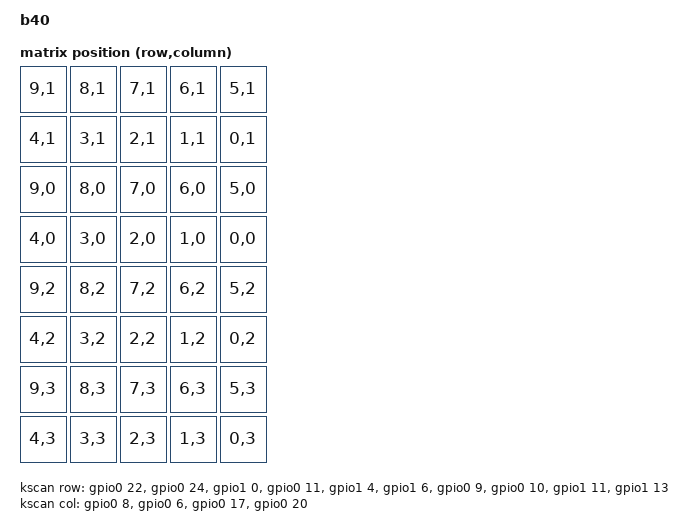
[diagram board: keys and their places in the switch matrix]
// This file was generated from a template. Edit it to match your keyboard.
// See https://docs.zephyrproject.org/4.1.0/hardware/porting/board_porting.html
// and https://zmk.dev/docs/development/hardware-integration/new-shield for more
// instructions.

/dts-v1/;
#include <nordic/nrf52840_qiaa.dtsi>
#include <dt-bindings/zmk/matrix_transform.h>

#include "b40-pinctrl.dtsi"
#include "b40-layouts.dtsi"

/ {
    model = "b40";
    compatible = "b40";

    chosen {
        zephyr,code-partition = &code_partition;
        zephyr,sram = &sram0;
        zephyr,flash = &flash0;
        // Uncomment this if you enabled one of the "vddh" nodes below.
        // zmk,battery = &vbatt;
        zmk,physical-layout = &default_layout;
    };

    kscan: kscan {
        // If the hardware does not use a switch matrix, change this to the
        // appropriate driver and update the properties below to match.
        // See https://zmk.dev/docs/config/kscan for supported key scan drivers.
        compatible = "zmk,kscan-gpio-matrix";
        // Set this to "col2row" or "row2col" to match the hardware. If using
        // "row2col", change the col-gpios to (GPIO_ACTIVE_HIGH | GPIO_PULL_DOWN)
        // and the row-gpios to GPIO_ACTIVE_HIGH.
        diode-direction = "col2row";
        wakeup-source;

        // Bancouver40 matrix wiring, using the labels printed on the PCB.
        // Columns: D0 -> C2, D1 -> C1, D2 -> C3, D3 -> C4.
        col-gpios
            = <&gpio0 8 GPIO_ACTIVE_HIGH>
            , <&gpio0 6 GPIO_ACTIVE_HIGH>
            , <&gpio0 17 GPIO_ACTIVE_HIGH>
            , <&gpio0 20 GPIO_ACTIVE_HIGH>
            ;

        // Rows: D4 -> R10 through D15 -> R1.
        row-gpios
            = <&gpio0 22 (GPIO_ACTIVE_HIGH | GPIO_PULL_DOWN)>
            , <&gpio0 24 (GPIO_ACTIVE_HIGH | GPIO_PULL_DOWN)>
            , <&gpio1 0 (GPIO_ACTIVE_HIGH | GPIO_PULL_DOWN)>
            , <&gpio0 11 (GPIO_ACTIVE_HIGH | GPIO_PULL_DOWN)>
            , <&gpio1 4 (GPIO_ACTIVE_HIGH | GPIO_PULL_DOWN)>
            , <&gpio1 6 (GPIO_ACTIVE_HIGH | GPIO_PULL_DOWN)>
            , <&gpio0 9 (GPIO_ACTIVE_HIGH | GPIO_PULL_DOWN)>
            , <&gpio0 10 (GPIO_ACTIVE_HIGH | GPIO_PULL_DOWN)>
            , <&gpio1 11 (GPIO_ACTIVE_HIGH | GPIO_PULL_DOWN)>
            , <&gpio1 13 (GPIO_ACTIVE_HIGH | GPIO_PULL_DOWN)>
            ;
    };

    default_transform: default_transform {
        // The electrical matrix is R1-R10 by C1-C4. Map it to the physical
        // 4-row by 10-column ortholinear layout, accounting for the reversed
        // R10-to-R1 and C2-before-C1 wiring order above.
        compatible = "zmk,matrix-transform";
        columns = <4>;
        rows = <10>;

        map = <
            RC(9, 1) RC(8, 1) RC(7, 1) RC(6, 1) RC(5, 1)
            RC(4, 1) RC(3, 1) RC(2, 1) RC(1, 1) RC(0, 1)
            RC(9, 0) RC(8, 0) RC(7, 0) RC(6, 0) RC(5, 0)
            RC(4, 0) RC(3, 0) RC(2, 0) RC(1, 0) RC(0, 0)
            RC(9, 2) RC(8, 2) RC(7, 2) RC(6, 2) RC(5, 2)
            RC(4, 2) RC(3, 2) RC(2, 2) RC(1, 2) RC(0, 2)
            RC(9, 3) RC(8, 3) RC(7, 3) RC(6, 3) RC(5, 3)
            RC(4, 3) RC(3, 3) RC(2, 3) RC(1, 3) RC(0, 3)
        >;
    };

    // If you are powering the SoC from the VDDH pin, uncomment this block.
    // Otherwise, delete it.

    // vbatt: vbatt {
    //     compatible = "zmk,battery-nrf-vddh";
    // };

    // If you are powering the SoC from the VDD pin and you have a voltage divider
    // routed to an analog pin to read the battery voltage, uncomment this block
    // and assign the correct ADC channel and resistance values.
    // Otherwise, delete it.

    // vbatt: vbatt {
    //     compatible = "voltage-divider";
    //     io-channels = <&adc 2>;
    //     output-ohms = <2000000>;
    //     full-ohms = <(2000000 + 806000)>;
    // };
};

// Uncomment this to switch from the LDO to the DC/DC regulator on REG0.
// Do not enable the DC/DC regulator without an LC filter connected to the DCCH
// pin, or the keyboard will not boot until an LC filter is connected.
// &reg0 {
//     status = "okay";
// };

// Uncomment this to switch from the LDO to the DC/DC regulator on REG1.
// Do not enable the DC/DC regulator without an LC filter connected to the DCC
// pin, or the keyboard will not boot until an LC filter is connected.
// &reg1 {
//     regulator-initial-mode = <NRF5X_REG_MODE_DCDC>;
// };

&adc {
    status = "okay";
};

&gpiote {
    status = "okay";
};

&gpio0 {
    status = "okay";
};

&gpio1 {
    status = "okay";
};

&uart0 {
    compatible = "nordic,nrf-uarte";
    current-speed = <115200>;
    pinctrl-0 = <&uart0_default>;
    pinctrl-1 = <&uart0_sleep>;
    pinctrl-names = "default", "sleep";
};

// If you use the NFC pins as GPIOs, uncomment this. Otherwise, remove it.
// &uicr {
//     nfct-pins-as-gpios;
// };

zephyr_udc0: &usbd {
    status = "okay";
};

&flash0 {
    // Adjust this flash map as is necessary for your board. For more information, see
    // https://docs.zephyrproject.org/4.1.0/services/storage/flash_map/flash_map.html#relationship-with-devicetree
    partitions {
        compatible = "fixed-partitions";
        #address-cells = <1>;
        #size-cells = <1>;

        code_partition: partition@1000 {
            reg = <DT_SIZE_K(4) DT_SIZE_K(844)>;
        };

        // If using a bootloader with SoftDevice included, replace the code_partition
        // node above with the following. If using SoftDevice v7, change 26000 to 27000.

        // sd_partition: partition@0 {
        //     reg = <0x0 <DT_SIZE_K(4)>;
        // };
        // code_partition: partition@26000 {
        //     reg = <DT_SIZE_K(152) DT_SIZE_K(792)>;
        // };

        // The flash starting at 0x000d4000 and ending at
        // 0x000f3fff is reserved for use by the application.

        // Storage partition will be used by NVS if enabled.
        storage_partition: partition@d4000 {
            reg = <DT_SIZE_K(848) DT_SIZE_K(128)>;
        };

        boot_partition: partition@f4000 {
            reg = <DT_SIZE_K(976) DT_SIZE_K(48)>;
        };
    };
};
